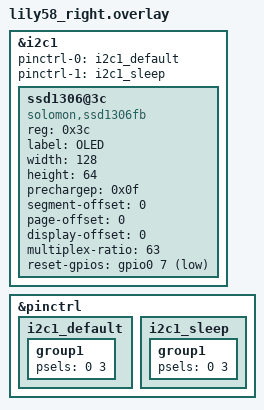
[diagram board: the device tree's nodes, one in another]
&i2c1 {
    status = "okay";
    pinctrl-0 = <&i2c1_default>;
    pinctrl-1 = <&i2c1_sleep>;
    pinctrl-names = "default", "sleep";

    ssd1306@3c {
        compatible = "solomon,ssd1306fb";
        reg = <0x3c>;
        label = "OLED";
        width = <128>;
        height = <64>;

        prechargep = <0x0f>;
        segment-offset = <0>;
        page-offset = <0>;
        display-offset = <0>;
        multiplex-ratio = <63>;
        reset-gpios = <&gpio0 7 GPIO_ACTIVE_LOW>;
    };
};

&pinctrl {
    i2c1_default: i2c1_default {
        group1 {
            psels = <0 3>;
        };
    };

    i2c1_sleep: i2c1_sleep {
        group1 {
            psels = <0 3>;
        };
    };
};
